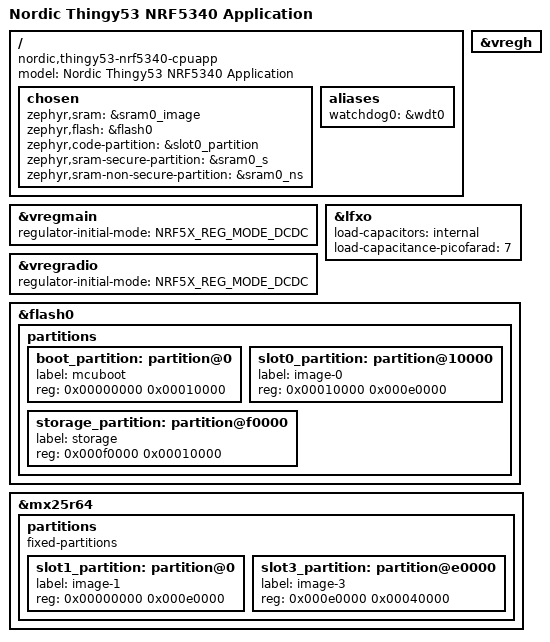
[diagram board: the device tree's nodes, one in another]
/*
 * Copyright (c) 2021 Nordic Semiconductor ASA
 *
 * SPDX-License-Identifier: Apache-2.0
 */

/dts-v1/;
#include <nordic/nrf5340_cpuapp_qkaa.dtsi>
#include "thingy53_nrf5340_common.dtsi"
#include <../boards/common/usb/cdc_acm_serial.dtsi>

/ {
	model = "Nordic Thingy53 NRF5340 Application";
	compatible = "nordic,thingy53-nrf5340-cpuapp";

	chosen {
		zephyr,sram = &sram0_image;
		zephyr,flash = &flash0;
		zephyr,code-partition = &slot0_partition;
		zephyr,sram-secure-partition = &sram0_s;
		zephyr,sram-non-secure-partition = &sram0_ns;
	};

	aliases {
		watchdog0 = &wdt0;
	};
};

&vregmain {
	regulator-initial-mode = <NRF5X_REG_MODE_DCDC>;
};

&vregradio {
	regulator-initial-mode = <NRF5X_REG_MODE_DCDC>;
};

&vregh {
	status = "okay";
};

&lfxo {
	load-capacitors = "internal";
	load-capacitance-picofarad = <7>;
};

/* Include default memory partition configuration file */
#include <nordic/nrf5340_cpuapp_partition.dtsi>
/delete-node/ &boot_partition;
/delete-node/ &slot0_partition;
/delete-node/ &slot1_partition;
/delete-node/ &storage_partition;

&flash0 {
	partitions {
		boot_partition: partition@0 {
			label = "mcuboot";
			reg = <0x00000000 0x00010000>;
		};

		slot0_partition: partition@10000 {
			label = "image-0";
			reg = <0x00010000 0x000e0000>;
		};

		storage_partition: partition@f0000 {
			label = "storage";
			reg = <0x000f0000 0x00010000>;
		};
	};
};

&mx25r64 {
	partitions {
		compatible = "fixed-partitions";
//		ranges;
		#address-cells = <1>;
		#size-cells = <1>;

		slot1_partition: partition@0 {
			label = "image-1";
			reg = <0x00000000 0x000e0000>;
		};

		slot3_partition: partition@e0000 {
			label = "image-3";
			reg = <0x000e0000 0x00040000>;
		};
	};
};
